# CPSW_CPSW_52800000h register map
Vendor: Texas Instruments
Registers are 32-bit, read-write, reset 0x0 unless marked. A register's access mark holds for its fields unless they carry their own. Offsets are as the file gives them; [hi:lo] are bit positions; {n}, {i} and the like mark numbered series; 'fields as' and 'values as' point back to an identical list.

## CPSW (part 2 of 4)
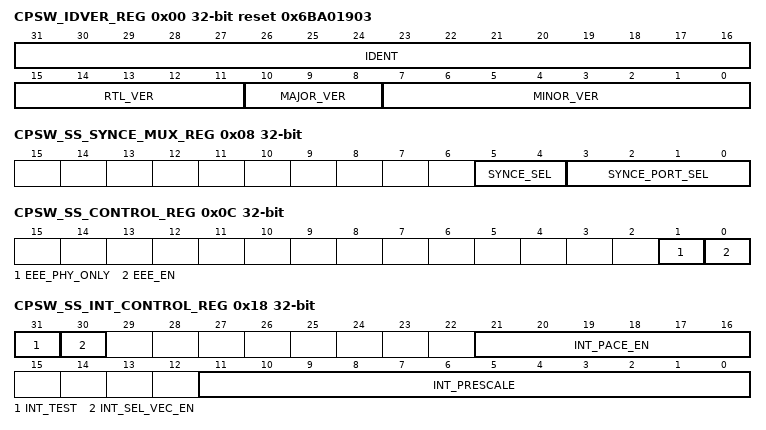
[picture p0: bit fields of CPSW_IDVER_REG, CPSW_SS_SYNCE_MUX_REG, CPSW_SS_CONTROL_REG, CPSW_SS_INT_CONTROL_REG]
0x00 CPSW_IDVER_REG ro reset 0x6BA01903 — ID Version Register.
  [31:16] IDENT — Identification value
  [15:11] RTL_VER — RTL version value
  [10:8] MAJOR_VER — Major version value
  [7:0] MINOR_VER — Minor version value
0x04 CPSW_SS_SYNCE_COUNT_REG — SS SYNCE Count Register.
  [31:0] SYNCE_CNT — SyncE Count Value - This value determines the toggle rate of the TS_SYNCE output. When this value is zero the TS_SYNCE output is disabled (low). When this value is non-zero, the TS_SYNCE output toggles each time the synce count value is reached. If this value is to be changed to another non-zero value then it should be written with a zero value before Writing the new non-zero value.
0x08 CPSW_SS_SYNCE_MUX_REG — SS Synce Mux Register.
  [5:4] SYNCE_SEL — Sync E Interface Select. 00 - GMIIn_MRCLK_I input clock from selected GMII port 01 - RMII_MHZ_50_CLK (same for all ports if RMII included) 10 - RGMIIn_RXC_I input clock from selected port (If RGMII included) 11 - SERDESn_RXCLK from selected port (If SGMII included)
  [3:0] SYNCE_PORT_SEL — Sync E Port Select - This field selects the port that will be used for the synchronous Ethernet receive clock. The port interface is selected with synce_sel. 0 - Port 1 1 - Port 2 ... 7 - Port 8 8-15 - Reserved
0x0C CPSW_SS_CONTROL_REG — SS Control Register.
  [1] EEE_PHY_ONLY — Energy Efficient Enable Phy Only Mode. 0 - The low power indicate state (LPI) includes gating off the CPPI_GCLK to the CPSW. 1 - The low power indicate state (LPI) does not gate the clock to the CPSW
  [0] EEE_EN — Energy Efficient Ethernet Enable. 0 - EEE is disabled 1 - EEE is enabled
0x18 CPSW_SS_INT_CONTROL_REG — SS Interrupt Control Register.
  [31] INT_TEST — Interrupt Test - Test bit to the interrupt pacing blocks
  [30] INT_SEL_VEC_EN — Interrupt Select Vector Enable. 0 - in_vector is an 8-bit mask for tx_pend, rx_pend, and rx_thresh_pend. 1 - in_vector is the 3-bit encoded value of the highest interrupt channel set for tx_pend, rx_pend, and rx_thresh_pend.
  [21:16] INT_PACE_EN — Interrupt Pacing Enable Bus. int_pace_en[0] - Enables C0_Rx_Pulse Pacing (0 is pacing bypass) int_pace_en[1] - Enables C0_Tx_Pulse Pacing (0 is pacing bypass) int_pace_en[2] - Enables C1_Rx_Pulse Pacing (0 is pacing bypass) int_pace_en[3] - Enables C1_Tx_Pulse Pacing (0 is pacing bypass) int_pace_en[4] - Enables C2_Rx_Pulse Pacing (0 is pacing bypass) int_pace_en[5] - Enables C2_Tx_Pulse Pacing (0 is pacing bypass)
  [11:0] INT_PRESCALE — Interrupt Counter Prescaler - The number of VBUSP_CLK periods in 4us.
0x1C CPSW_SS_STATUS_REG ro — SS Status Register.
  [0] EEE_CLKSTOP_ACK — Energy Efficient Ethernet clockstop acknowledge from CPSW
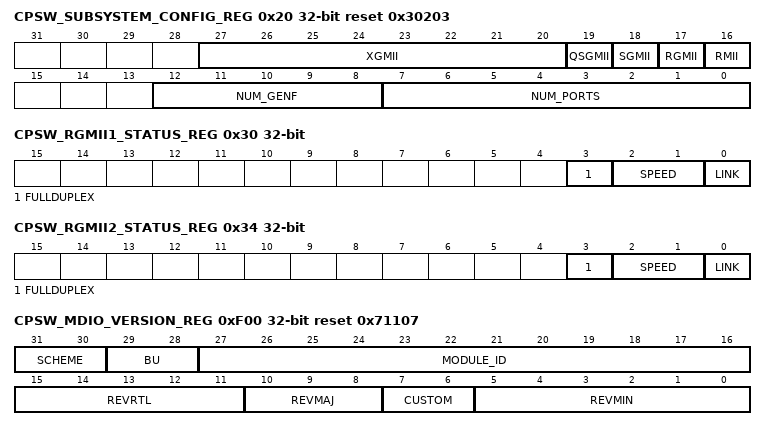
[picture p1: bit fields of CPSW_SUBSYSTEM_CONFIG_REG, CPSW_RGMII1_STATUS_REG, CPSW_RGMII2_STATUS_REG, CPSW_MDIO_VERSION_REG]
0x20 CPSW_SUBSYSTEM_CONFIG_REG ro reset 0x30203 — Subsystem Configuration Register.
  [27:20] XGMII — The Number of XGMII Ports included in the CPSW
  [19] QSGMII — QSGMII is included in the CPSW
  [18] SGMII — SGMII is included in the CPSW
  [17] RGMII — RGMII is included in the CPSW
  [16] RMII — RMII is included in the CPSW
  [12:8] NUM_GENF — The number of CPTS GENF outputs
  [7:0] NUM_PORTS — The total number of ports including the host port 0
0x30 CPSW_RGMII1_STATUS_REG ro — RGMII1 Status Register.
  [3] FULLDUPLEX — Rgmii1 Full-duplex 0 - Half-duplex 1 - Full-duplex
  [2:1] SPEED — Rgmii1 Speed 00 - 10Mbps 01 - 100Mbps 10 - 1000Mbps 11 - reserved
  [0] LINK — Rgmii1 Link Indicator 0 - Link is down 1 - Link is up
0x34 CPSW_RGMII2_STATUS_REG ro — RGMII2 Status Register.
  [3] FULLDUPLEX — Rgmii2 Full-duplex 0 - Half-duplex 1 - Full-duplex
  [2:1] SPEED — Rgmii2 Speed 00 - 10Mbps 01 - 100Mbps 10 - 1000Mbps 11 - reserved
  [0] LINK — Rgmii2 Link Indicator 0 - Link is down 1 - Link is up
0xF00 CPSW_MDIO_VERSION_REG ro reset 0x71107 — MDIO Version Register
  [31:30] SCHEME
  [29:28] BU
  [27:16] MODULE_ID
  [15:11] REVRTL — RTL version
  [10:8] REVMAJ — Major version
  [7:6] CUSTOM — Custom version
  [5:0] REVMIN — Minor version
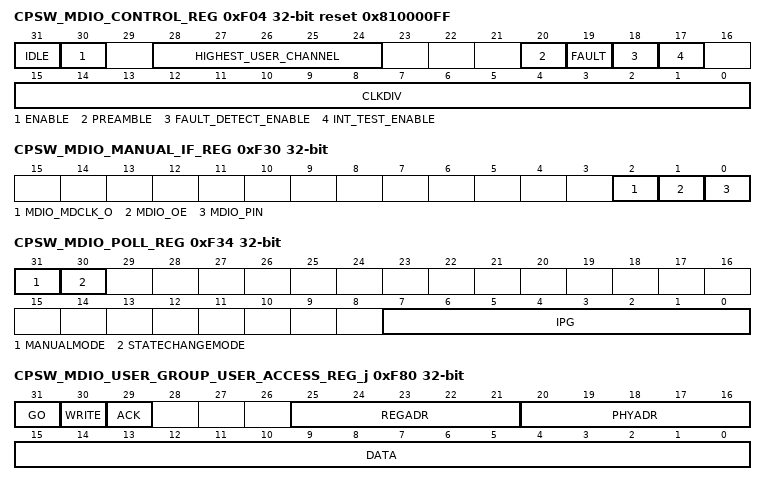
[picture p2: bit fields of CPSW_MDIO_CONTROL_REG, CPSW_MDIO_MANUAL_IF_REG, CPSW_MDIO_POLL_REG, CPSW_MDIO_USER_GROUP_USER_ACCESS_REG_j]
0xF04 CPSW_MDIO_CONTROL_REG access per field reset 0x810000FF — MDIO Control Register
  [31] IDLE ro — MDIO state machine IDLE. Set to 1 by the hardware when the state machine is in the idle state.
  [30] ENABLE rw — Enable control. Writing a 1 to this bit enables the MDIO state machine, writing a 0 disables it. If the MDIO state machine is active at the time it is disabled, it will complete the current operation before halting and setting the idle bit. If using byte access, the enable bit has to be the last bit written in this register.
  [28:24] HIGHEST_USER_CHANNEL ro — Highest user channel. This field specifies the highest useraccess channel that is available in the module and is currently set to 1. This implies that MDIOUserAccess1 is the highest available user access channel.
  [20] PREAMBLE rw — Preamble disable. Writing a 1 to this bit disables this device from sending MDIO frame preambles in clause 22 mode of operation. This bit has no effect in clause 45 mode of operation.
  [19] FAULT rw — Fault indicator. This bit is set to 1 if the MDIO pins fail to read back what the device is driving onto them. This indicates a physical layer fault and the module state machine is reset. Writing a 1 to it clears this bit.
  [18] FAULT_DETECT_ENABLE rw — Fault detect enable. This bit has to be set to 1 to enable the physical layer fault detection.
  [17] INT_TEST_ENABLE rw — Interrupt test enable. This bit can be set to 1 to enable the host to set the userint and linkint bits for test purposes.
  [15:0] CLKDIV rw — Clock Divider. This field specifies the division ratio between CLK and the frequency of MDCLK. MDCLK is disabled when clkdiv is set to 0. MDCLK frequency = clk frequency/(clkdiv+1).
0xF08 CPSW_MDIO_ALIVE_REG — MDIO Alive Register
  [31:0] ALIVE — MDIO Alive. Each of the 32 bits of this register is set if the most recent access to the PHY with address corresponding to the register bit number was acknowledged by the PHY, the bit is reset if the PHY fails to acknowledge the access. Both the user and polling accesses to a PHY will cause the corresponding alive bit to be updated. The alive bits are intended to be used to give an indication of the presence or not of the PHY with the corresponding address. Writing a 1 to any bit will clear it, writing a 0 has no effect.
0xF0C CPSW_MDIO_LINK_REG ro — MDIO Link Register
  [31:0] LINK — MDIO Link state. This register is updated after a read of the Generic Status Register of a PHY. The corresponding bit is set if the PHY with the corresponding address has link and the PHY acknowledges the read transaction. The bit is cleared to zero if the PHY indicates it does not have link or fails to acknowledge the read transaction. Writes to the register have no effect. In addition, in Normal Mode Operation, the status of the two PHYs specified in the MDIOUserPhySel registers can be determined using the MLINK input pins. This is determined by the linksel bit in the MDIOUserPhySel register. In State Change Mode the MLINK input pins are unused.
0xF10 CPSW_MDIO_LINK_INT_RAW_REG — MDIO Link Interrupt Raw Register
  [1:0] LINKINTRAW — MDIO link change event raw value. Normal mode operation: When asserted, a bit indicates that there was an MDIO link change event (i.e. change in the MDIOLink register) corresponding to the PHY address in the MDIOUserPhySel register. linkintraw[0] and linkintraw[1] correspond to MDIOUserPhySel0 and MDIOUserPhysel1, respectively. Writing a 1 will clear the event and writing 0 has no effect. If the int_test bit in the MDIOControl register is set, the host may set linkintraw bits to a 1 which may be used for test purposes. MDIO link change event raw value. State Change Mode operation: The linkintraw[0] bit will be asserted when any bit (for any PHY) in the MDIOAlive or MDIOLink registers changes due to MDIO operations. The linkintraw[1] bit is unused in State Change Mode. State Change Mode allows any state change in any PHY to issue an interrupt. If the int_test bit in the MDIOControl register is set, the host may set the linkintraw[0] bit high which may be used for test purposes.
0xF14 CPSW_MDIO_LINK_INT_MASKED_REG — MDIO Link Interrupt Masked Register
  [1:0] LINKINTMASKED — MDIO link change interrupt masked value. Normal mode operation: When asserted, a bit indicates that there was an MDIO link change event (i.e. change in the MDIOLink register) corresponding to the PHY address in the MDIOUserPhySel register and the corresponding linkint_enable bit was set. linkintmasked[0] and linkintmasked[1] correspond to MDIOUserPhySel0 and MDIOUserPhysel1, respectively. Writing a 1 will clear the interrupt and writing 0 has no effect. These masked interrupt bits are the MDIO_LINKINT[1:0] pin values. MDIO link change interrupt masked value. State Change Mode operation: The linkintmasked[0] bit will be asserted when linkintraw[0] is asserted and when the linkintmaskset bit is set to 1. Writing a 1 will clear linkintmasked[0] (and the MDIO_LINKINT[0] output) and writing 0 has no effect. The linkintmasked[1] bit is not used in State Change Mode (MDIO_LINKINT[1] is therefore also unused in State Change Mode).
0xF18 CPSW_MDIO_LINK_INT_MASK_SET_REG — MDIO Link Interrupt Mask Set Register
  [0] LINKINTMASKSET — MDIO link interrupt mask set. Normal Mode Operation: This register is not used in normal mode. In normal mode the MDIO_LINKINT[1:0] interrupts are enabled with the linkint_enable bit in the associated MDIOUserPhySel0/1 register. MDIO link interrupt mask set. State Change Mode Operation: Writing this bit to 1 will enable the MDIO link status change interrupt (MDIO_LINKINT[0]) to be asserted when linkintraw[0] is asserted.
0xF1C CPSW_MDIO_LINK_INT_MASK_CLEAR_REG — MDIO Link Interrupt Mask Clear Register
  [0] LINKINTMASKCLR — MDIO link interrupt mask clear. Normal Mode Operation: This register is not used in normal mode. In normal mode the MDIO_LINKINT[1:0] interrupts are enabled with the linkint_enable bit in the associated MDIOUserPhySel0/1 register. MDIO link interrupt mask clear. State Change Mode Operation: Writing this bit to 1 will disable the MDIO link status change interrupt (MDIO_LINKINT[0]) regardless of the linkintraw[0] bit value.
0xF20 CPSW_MDIO_USER_INT_RAW_REG — MDIO User Interrupt Raw Register
  [1:0] USERINTRAW — Raw value of MDIO user command complete event for MDIOUserAccess1 through MDIOUserAccess0, respectively. When asserted, a bit indicates that the previously scheduled PHY read or write command using that particular MDIOUserAccess register has completed. Writing a 1 will clear the event and writing 0 has no effect. If the int_test bit in the MDIOControl register is set, the host may set the userintraw bits to a 1. This mode may be used for test purposes.
0xF24 CPSW_MDIO_USER_INT_MASKED_REG — MDIO User Interrupt Masked Register
  [1:0] USERINTMASKED — Masked value of MDIO user command complete interrupt for MDIOUserAccess1 through MDIOUserAccess0, respectively. When asserted, a bit indicates that the previously scheduled PHY read or write command using that particular MDIOUserAccess register has completed and the corresponding userintmaskset bit is set to 1. Writing a 1 will clear the interrupt and writing 0 has no effect. If the int_test bit in the MDIOControl register is set, the host may set the userintmasked bits to a 1. This mode may be used for test purposes.
0xF28 CPSW_MDIO_USER_INT_MASK_SET_REG — MDIO User Interrupt Mask Set Register
  [1:0] USERINTMASKSET — MDIO user interrupt mask set for userintmasked[1:0], respectively. Writing a bit to 1 will enable MDIO user command complete interrupts for that particular MDIOUserAccess register. MDIO user interrupt for a particular MDIOUserAccess register is disabled if the corresponding bit is 0. Writing a 0 to this register has no effect.
0xF2C CPSW_MDIO_USER_INT_MASK_CLEAR_REG — MDIO User Interrupt Mask Clear Register
  [1:0] USERINTMASKCLR — MDIO user command complete interrupt mask clear for userintmasked[1:0], respectively. Writing a bit to 1 will disable further user command complete interrupts for that particular MDIOUserAccess register. Writing a 0 to this register has no effect.
0xF30 CPSW_MDIO_MANUAL_IF_REG — MDIO Manual Interface Register
  [2] MDIO_MDCLK_O — MDIO Clock Output - This value is the MDCLK_O output value when the manualmode bit is set in the MDIO_POLL_IPG register.
  [1] MDIO_OE — MDIO Output Enable - This value is inverted and output on the MDIO_OE_N output when the manualmode bit is set in the MDIO_POLL_IPG register.
  [0] MDIO_PIN — MDIO_Pin Value - This is the external MDIO data pin value when the manualmode bit is set in the MDIO_POLL_IPG register. That is, this value is driven on the MDIO_O (the MDIO serial data output) when MDIO_OE is asserted. The read value for this bit comes from MDIO_I (the MDIO serial data input). If MDIO_OE is asserted and MDIO_PIN is written with a 1 then MDIO_PIN should read a 1 if there are no external devices pulling the MDIO data line low.
0xF34 CPSW_MDIO_POLL_REG — MDIO Poll Register
  [31] MANUALMODE — Polling Inter Packet Gap Value - This value is the number of MDCLK_O clocks between each poll when polling is enabled.
  [30] STATECHANGEMODE — State Change Mode - When set, the MDIO is operating in State Change Mode. When clear, the MDIO is operating in normal mode. State change mode effects interrupt operations.
  [7:0] IPG — Manual Mode - When set, the MDIO pins are directly controlled by software through the bits in the MDIOManual_IF register
0xF38 CPSW_MDIO_POLL_EN_REG reset 0xFFFFFFFF — MDIO Poll Enable Register
  [31:0] POLL_EN — Poll Enable - When set, the bit indicates that the associated PHY will be included in polling operations. When clear, the associated PHY will not be polled. Each bit in this field is associated with a PHY. Bit zero is associated with PHY 0 and so on. Due to a limitation in the hardware, bit 31 must always be set, regardless of the value of the preamble disable bit in the MDIO_CONTROL register. However, there does not have to be a PHY at address 31.
0xF3C CPSW_MDIO_CLAUS45_REG — MDIO Clause45 Register
  [31:0] CLAUSE45 — MDIO clause 45 mode. When a clause45 bit is cleared, the PHY associated with the clause45 bit is operating in the clause 22 mode. When set, the PHY associated with the clause45 bit is operating in the clause 45 mode. Bit 0 is associated with PHY 0 and so on.
0xF40 CPSW_MDIO_USER_ADDR0_REG — MDIO Address 0 Register
  [15:0] USER_ADDR0 — User Address 0 - In clause 45 mode, this field value is the address transferred in the address transfer inititated before each MDIOUserAccess0 access. This is not used for PHYs operating in clause22 mode as there is no address transfer preceeding each MDIOUserAccess0 access.
0xF44 CPSW_MDIO_USER_ADDR1_REG — MDIO Address 1 Register
  [15:0] USER_ADDR1 — User Address 1 - In clause 45 mode, this field value is the address transferred in the address transfer inititated before each MDIOUserAccess1 access. This is not used for PHYs operating in clause22 mode as there is no address transfer preceeding each MDIOUserAccess1 access.
0xF80 CPSW_MDIO_USER_GROUP_USER_ACCESS_REG_j — MDIO User Access Register
  [31] GO — Go. Writing a 1 to this bit causes the MDIO state machine to perform an MDIO access when it is convenient for it to do so, this is not an instantaneous process. Writing a 0 to this bit has no effect. This bit is write able only if the MDIO state machine is enabled. This bit will self clear when the requested access has been completed. Any writes to the MDIOUserAccess0 register are blocked when the go bit is 1. If byte access is being used, the go bit should be written last.
  [30] WRITE — Write enable. Setting this bit to a 1 causes the MDIO transaction to be a register write, otherwise it is a register read.
  [29] ACK — Acknowledge. This bit is set if the PHY acknowledged the read transaction.
  [25:21] REGADR — Register address. This field specifies the PHY register to be accessed for this transaction in clause 22 mode or the MMD value in clause 45 mode.
  [20:16] PHYADR — PHY address. This field specifies the PHY to be accessed for this transaction.
  [15:0] DATA — User data. The data value read from or to be written to the specified PHY register.
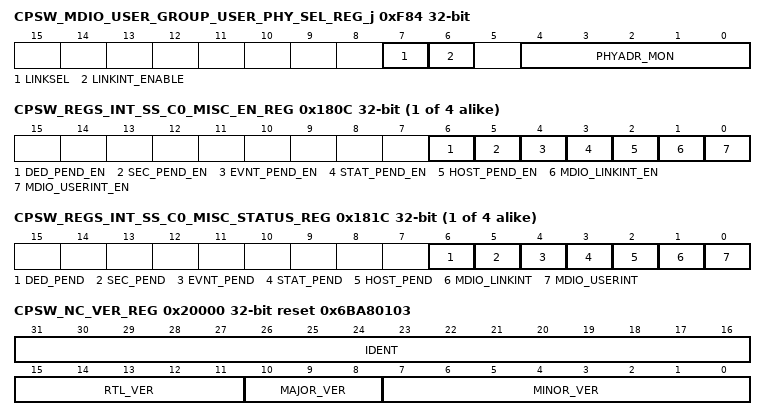
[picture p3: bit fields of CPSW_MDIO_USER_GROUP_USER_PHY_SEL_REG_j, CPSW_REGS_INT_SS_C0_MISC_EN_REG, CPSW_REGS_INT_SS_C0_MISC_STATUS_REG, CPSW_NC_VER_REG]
0xF84 CPSW_MDIO_USER_GROUP_USER_PHY_SEL_REG_j — MDIO User PHY Select Register
  [7] LINKSEL — Link status determination select. Set to 1 to determine link status using the MLINK pin. Default value is 0 which implies that the link status is determined by the MDIO state machine.
  [6] LINKINT_ENABLE — Link change interrupt enable. Set to 1 to enable link change status interrupts for PHY address specified in phyadr_mon. Link change interrupts are disabled if this bit is set to 0.
  [4:0] PHYADR_MON — PHY address whose link status is to be monitored.
{0x1800+0x40*i} CPSW_REGS_INT_SS_C{i}_TH_THRESH_PULSE_EN_REG (i=0..3) — Core {i} THost Threshold Pulse Interrupt Enable Register
  [7:0] TH_THRESH_PULSE_EN — Core {i} THost Threshold Enable - Each bit in this register corresponds to the bit in the THost threshold interrupt that is enabled to generate an interrupt on C{i}_TH_THRESH_PULSE.
{0x1804+0x40*i} CPSW_REGS_INT_SS_C{i}_TH_PULSE_EN_REG (i=0..3) — Core {i} THost Pulse Interrupt Enable Register
  [7:0] TH_PULSE_EN — Core {i} THost Enable - Each bit in this register corresponds to the bit in the THost interrupt that is enabled to generate an interrupt on C{i}_TH_PULSE.
{0x1808+0x40*i} CPSW_REGS_INT_SS_C{i}_FH_PULSE_EN_REG (i=0..3) — Core {i} FHost Pulse Interrupt Enable Register
  [7:0] FH_PULSE_EN — Core {i} FHost Interrupt Enable - Each bit in this register corresponds to the bit in the FHost interrupt that is enabled to generate an interrupt on C{i}_FH_PULSE.
{0x180C+0x40*i} CPSW_REGS_INT_SS_C{i}_MISC_EN_REG (i=0..3) — Core {i} Misc Interrupt Enable Register
  [6] DED_PEND_EN — Core {i} MISC DED Memory Protect Error Interrupt Enable - enabled to generate an interrupt on C{i}_Misc_PULSE
  [5] SEC_PEND_EN — Core {i} MISC SEC Memory Protect Error Interrupt Enable - enabled to generate an interrupt on C{i}_Misc_PULSE
  [4] EVNT_PEND_EN — Core {i} MISC CPTS Event Interrupt Enable - enabled to generate an interrupt on C{i}_Misc_PULSE
  [3] STAT_PEND_EN — Core {i} MISC Statistics Interrupt Enable - Logical OR of all port statistics bits (bits n downto 0) - enabled to generate an interrupt on C{i}_Misc_PULSE
  [2] HOST_PEND_EN — Core {i} MISC Host Interrupt Enable - enabled to generate an interrupt on C{i}_Misc_PULSE
  [1] MDIO_LINKINT_EN — Core {i} MISC MDIO linkint - Logical OR of bits 1 and 0 - enabled to generate an interrupt on C{i}_Misc_PULSE
  [0] MDIO_USERINT_EN — Core {i} MISC_MDIO userint interrupt enable - Logical OR of bits 1 and 0 - enabled to generate an interrupt on C{i}_Misc_PULSE
{0x1810+0x40*i} CPSW_REGS_INT_SS_C{i}_TH_THRESH_PULSE_STATUS_REG ro (i=0..3) — THost Threshold Pulse Interrupt Status Register
  [7:0] TH_THRESH_PULSE_STATUS — Core {i} THost Threshold Masked Interrupt Status - Each bit in this read only register corresponds to the bit in the THost threshold interrupt that is enabled and generating an interrupt on C{i}_TH_THRESH_PULSE.
{0x1814+0x40*i} CPSW_REGS_INT_SS_C{i}_TH_PULSE_STATUS_REG ro (i=0..3) — THost Pulse Interrupt Status Register
  [7:0] TH_PULSE_STATUS — Core {i} THost Pulse Interrupt Status Register - Each bit in this read only register corresponds to the bit in the Rx interrupt that is enabled and generating an interrupt on C{i}_TH_PULSE.
{0x1818+0x40*i} CPSW_REGS_INT_SS_C{i}_FH_PULSE_STATUS_REG ro (i=0..3) — FHost Pulse Interrupt Status Register
  [7:0] FH_PULSE_STATUS — Core {i} FHost Pulse Interrupt Status Register - Each bit in this read only register corresponds to the bit in the Tx interrupt that is enabled and generating an interrupt on C{i}_FH_PULSE .
{0x181C+0x40*i} CPSW_REGS_INT_SS_C{i}_MISC_STATUS_REG (i=0..3) — Misc Interrupt Status Register - Set bits in this register indicate that an enabled interrupt is asserted
  [6] DED_PEND — Core {i} MISC DED Memory Protect Error Interrupt
  [5] SEC_PEND — Core {i} MISC SEC Memory Protect Error Interrupt
  [4] EVNT_PEND — Core {i} MISC CPTS Event Interrupt
  [3] STAT_PEND — Core {i} MISC Statistics Interrupt - Logical OR of bits n downto 0
  [2] HOST_PEND — Core {i} MISC Host Interrupt Enable
  [1] MDIO_LINKINT — Core {i} MISC MDIO linkint - Logical OR of bits 1 and 0
  [0] MDIO_USERINT — Core {i} MISC_MDIO userint interrupt - Logical OR of bits 1 and 0
{0x1820+0x40*i} CPSW_REGS_INT_SS_C{i}_TH_IMAX_REG (i=0..3) — Core {i} THost Interrupt Max Register Register
  [5:0] TH_IMAX — Core {i} THost Interrupts per millisecond - The maximum number of interrupts per millisecond generated on C{i}_TH_PULSE if pacing is enabled for this interrupt.
{0x1824+0x40*i} CPSW_REGS_INT_SS_C{i}_FH_IMAX_REG (i=0..3) — Core {i} FHost Interrupt Max Register Register
  [5:0] FH_IMAX — Core {i} FHost Interrupts per millisecond - The maximum number of interrupts per millisecond generated on C{i}_FH_PULSE if pacing is enabled for this interrupt.
0x20000 CPSW_NC_VER_REG ro reset 0x6BA80103 — CPSW ID Version
  [31:16] IDENT — Identification Value
  [15:11] RTL_VER — RTL Version Value
  [10:8] MAJOR_VER — Major Version Value
  [7:0] MINOR_VER — Minor Version Value
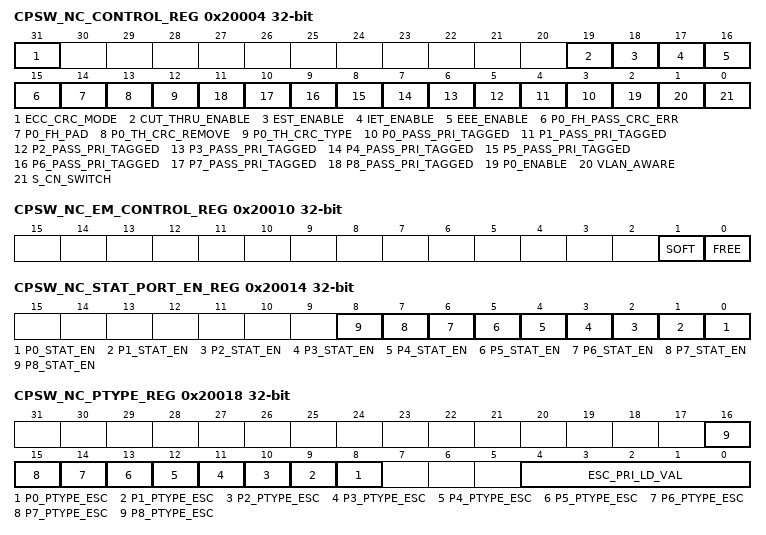
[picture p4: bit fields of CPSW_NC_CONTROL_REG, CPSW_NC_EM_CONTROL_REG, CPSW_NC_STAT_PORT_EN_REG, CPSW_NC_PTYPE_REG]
0x20004 CPSW_NC_CONTROL_REG — CPSW Switch Control
  [31] ECC_CRC_MODE — ECC CRC Mode - 0 - ECC errors induced through the ECC aggregator flip bits in the packet headers (not in packet data). 1 - ECC errors induced through the ECC aggregator flip bits in the packet data (not in the packet headers).
  [19] CUT_THRU_ENABLE — Cut Thru Enable - 0 - Cut Thru disabled. 1 - Cut Thru enabled .
  [18] EST_ENABLE — Enhanced Scheduled Traffic enable (EST) - 0 - EST is disabled. 1 - EST is enabled
  [17] IET_ENABLE — Intersperced Express Traffic enable (IET) - 0 - IET is disabled. 1 - IET is enabled.
  [16] EEE_ENABLE — Energy Efficient Ethernet enable - 0 - Energy Efficient Ethernet is disabled. 1 - Energy Efficient Ethernet is enabled.
  [15] P0_FH_PASS_CRC_ERR — Port 0 Pass Received CRC errors - 0 - Packets received with CRC errors on port 0 are dropped. 1 - Packets received with CRC errors on port 0 are transferred to the destination ports.
  [14] P0_FH_PAD — Port 0 Receive Short Packet Pad - 0 - short packets are dropped. 1 - short packets are padded to 64-bytes (with pad and added CRC) if the CRC is not passed in. Short packets are dropped if the CRC is passed (in the Info0 word).
  [13] P0_TH_CRC_REMOVE — Port 0 Transmit CRC remove - 0 - Do not remove the CRC on Port 0 THost (egress) packets. 1 - Remove the CRC on all Port 0 THost (egress) packets.
  [12] P0_TH_CRC_TYPE — Port 0 Transmit CRC type - The type of CRC on all Port 0 transmit packets (egress), regardless of the CRC type of in ingress Ethernet port. This bit is present only if psi_cast = 1. 0 - Ethernet CRC on Port 0 Egress. 1 - Castagnoli CRC on Port 0 Egress (if psi_cast = 1).
  [n+3] P{n}_PASS_PRI_TAGGED (n=0..8) — Port {n} Pass Priority Tagged - 0 - Priority tagged packets have the zero VID replaced with the input port Enet_P{n}_PORT_VLAN[11:0] on ingress. 1 - Priority tagged packets are processed unchanged.
  [2] P0_ENABLE — Port 0 Enable - 0 - Port 0 is disabled 1 - Port 0 is enabled
  [1] VLAN_AWARE — VLAN Aware Mode - 0 - CPSW_NU is in the VLAN unaware mode. 1 - CPSW_NU is in the VLAN aware mode.
  [0] S_CN_SWITCH — Service or Customer VLAN switch. 0 - Customer switch. VLAN processing uses the inner_vlan_ltype. 1 - Service switch. VLAN processing uses the outer_vlan_ltype.
0x2000C CPSW_NC_STATUS_REG ro reset 0x1 — CPSW Status
  [0] CPPI_IDLE — CPPI Idle - Indicates when set that the CPPI port transmit and receive are idle.
0x20010 CPSW_NC_EM_CONTROL_REG — CPSW Emulation Control
  [1] SOFT — Emulation Soft Bit
  [0] FREE — Emulation Free Bit
0x20014 CPSW_NC_STAT_PORT_EN_REG — CPSW Statistics Port Enable
  [n] P{n}_STAT_EN (n=0..8) — Port {n} Statistics Enable 0 - Statistics are disabled for the port. 1 - Statistics are enabled for the port.
0x20018 CPSW_NC_PTYPE_REG — CPSW Transmit Priority Type
  [n+8] P{n}_PTYPE_ESC (n=0..8) — Port {n} Priority Type Escalate - 0 - Priority Type Fixed. 1 - Priority Type Escalate
  [4:0] ESC_PRI_LD_VAL — Escalate Priority Load Value - When a port is in escalate priority, this is the number of higher priority packets sent before the next lower priority is allowed to send a packet. Escalate priority allows lower priority packets to be sent at a fixed rate relative to the next higher priority. The min value of esc_pri_ld_val = 2.
0x2001C CPSW_NC_SOFT_IDLE_REG — CPSW Software Idle
  [0] SOFT_IDLE — Software Idle - 0 - Software idle not commanded. 1 - Command CPSW software idle. When set, port 0 packet DMA operations stop at the next packet boundary.
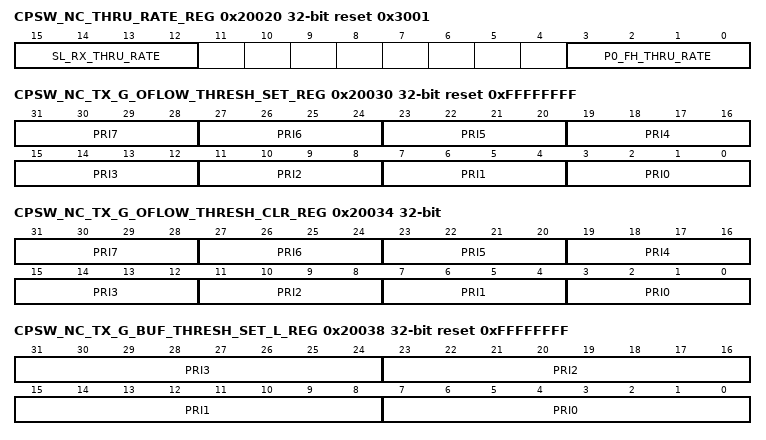
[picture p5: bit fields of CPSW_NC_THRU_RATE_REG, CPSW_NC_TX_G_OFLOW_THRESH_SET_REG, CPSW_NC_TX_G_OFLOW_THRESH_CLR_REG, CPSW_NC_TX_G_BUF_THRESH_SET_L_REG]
0x20020 CPSW_NC_THRU_RATE_REG reset 0x3001 — CPSW Thru Rate
  [15:12] SL_RX_THRU_RATE — This is not a field intended to be changed by software
  [3:0] P0_FH_THRU_RATE — This is not a field intended to be changed by software
0x20024 CPSW_NC_GAP_THRESH_REG reset 0xB — CPSW Transmit FIFO Short Gap Threshold
  [4:0] GAP_THRESH — Ethernet Port Short Gap Threshold - This is the Ethernet port associated FIFO transmit block usage value for triggering transmit short gap (when short gap is enabled).
0x2002C CPSW_NC_EEE_PRESCALE_REG — CPSW Energy Efficient Ethernet Prescale Value
  [11:0] EEE_PRESCALE — Energy Efficient Ethernet Prescale count load value - This value is loaded into the EEE pre-scale counter each time the pre-scale count decrements to zero. The EEE counters are enabled to decrement each time the pre-scale counter reaches zero (and the EEE counters are enabled to count time). If this value is zero then the EEE counters decrement on every clock. If this value is 0x001 then the counters decrement on every other clock (and so on).
0x20030 CPSW_NC_TX_G_OFLOW_THRESH_SET_REG reset 0xFFFFFFFF — CPSW PFC Tx Global Out Flow Threshold Set
  [4n+3:4n] PRI{n} (n=0..7) — Priority Based Flow Control Global Outflow Usage Threshold for Pri {n}
0x20034 CPSW_NC_TX_G_OFLOW_THRESH_CLR_REG — CPSW PFC Tx Global Out Flow Threshold Clear
  fields as CPSW_NC_TX_G_OFLOW_THRESH_SET_REG
0x20038 CPSW_NC_TX_G_BUF_THRESH_SET_L_REG reset 0xFFFFFFFF — CPSW PFC Global Tx Buffer Threshold Set Low
  [8n+7:8n] PRI{n} (n=0..3) — Priority Based Flow Control Global Buffer Usage Threshold for Priority {n}
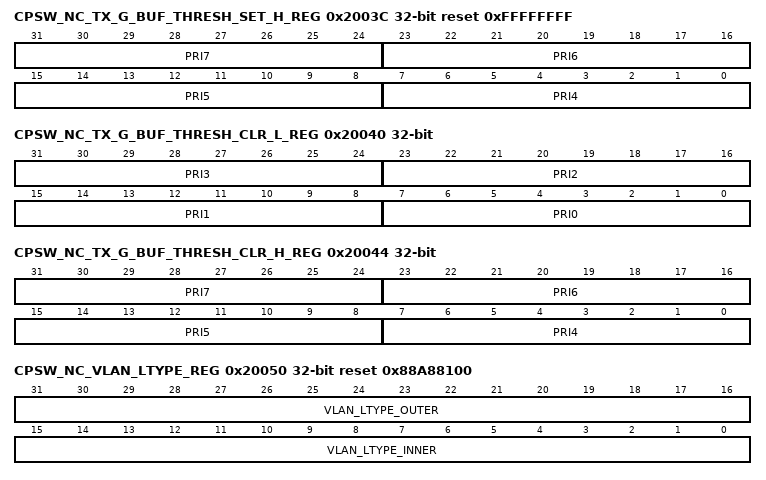
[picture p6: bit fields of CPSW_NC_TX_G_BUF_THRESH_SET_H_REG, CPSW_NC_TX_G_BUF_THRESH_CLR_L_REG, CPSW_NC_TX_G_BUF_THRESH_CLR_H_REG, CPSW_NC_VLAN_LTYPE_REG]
0x2003C CPSW_NC_TX_G_BUF_THRESH_SET_H_REG reset 0xFFFFFFFF — CPSW PFC Global Tx Buffer Threshold Set High
  [8n-25:8n-32] PRI{n} (n=4..7) — Priority Based Flow Control Global Buffer Usage Threshold for Priority {n}
0x20040 CPSW_NC_TX_G_BUF_THRESH_CLR_L_REG — CPSW PFC Global Tx Buffer Threshold Clear Low
  fields as CPSW_NC_TX_G_BUF_THRESH_SET_L_REG
0x20044 CPSW_NC_TX_G_BUF_THRESH_CLR_H_REG — CPSW PFC Global Tx Buffer Threshold Clear High
  fields as CPSW_NC_TX_G_BUF_THRESH_SET_H_REG
0x20050 CPSW_NC_VLAN_LTYPE_REG reset 0x88A88100 — VLAN Length/type
  [31:16] VLAN_LTYPE_OUTER — Outer VLAN LType
  [15:0] VLAN_LTYPE_INNER — Inner VLAN LType
0x20054 CPSW_NC_EST_TS_DOMAIN_REG — Enhanced Scheduled Traffic Host Event Domain
  [7:0] EST_TS_DOMAIN — Enhanced Scheduled Traffic domain. This value is used as the domain in the CPTS event to indicate that the event came from EST.
0x20058 CPSW_NC_CUT_THRESHOLD_REG — Cut-thru Threshold
  [3:0] CUT_THRESH — Cut-thru Threshold - This is not intended to be changed by software
0x2005C CPSW_NC_FREQUENCY_REG — CPSW CPPI_CLK Frequency in Mhz
  [9:0] CPSW_FREQ — CPSW Frequency - This is the frequency in Mhz of the VBUSP_GCLK. The frequency is rounded to the nearest Mhz. This value is used in auto speed detection for cut-thru operations.
0x20060 CPSW_NC_CUT_IET_HOLD_CNT_LD_VAL_REG reset 0x64 — IET Hold Count Load Value
  [7:0] CUT_IET_HOLD_CNT_LD_VAL — Cut-thru IET Hold Count Load Value - This value is loaded into counters to count the time that cut-thru packets are allowed to prempt traffic in advance in order to reduce cut-thru latency with IET operations. This is not intended to be changed by software.
{0x20100+4i} CPSW_NC_TX_PRI{i}_MAXLEN_REG reset 0x7E8 (i=0..7) — Transmit Priority {i} Maximum Length
  [13:0] TX_PRI{i}_MAXLEN — This value determines the maximum packet length that will be transmitted on priority {i} Ethernet egress for all Ethernet ports. The packet length compared to the maximum length value is the ingress packet length (not the actual egress packet length which is the length before VLAN addition or removal or any other egress processing). Packets on a priority that are larger than this value are dropped.
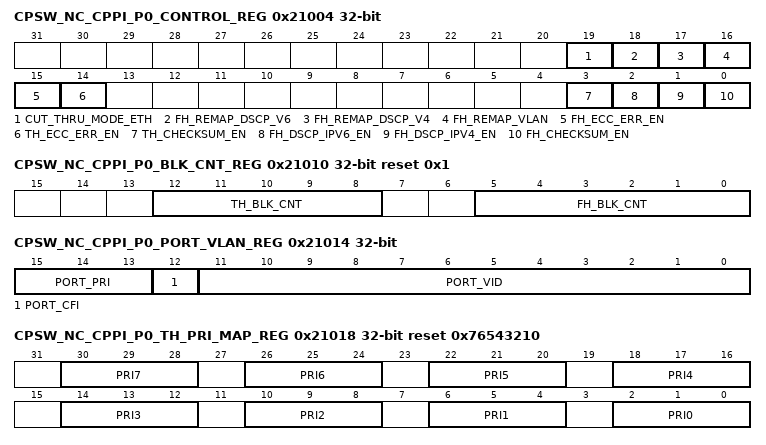
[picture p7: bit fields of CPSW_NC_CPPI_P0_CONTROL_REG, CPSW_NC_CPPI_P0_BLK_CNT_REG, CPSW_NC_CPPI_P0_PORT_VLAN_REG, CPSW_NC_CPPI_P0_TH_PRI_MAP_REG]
0x21004 CPSW_NC_CPPI_P0_CONTROL_REG — CPPI Port 0 Control
  [19] CUT_THRU_MODE_ETH — Port 0 Cut-Thru Mode - Packets always egress from the host port (CPPI egress) store-and-forward regardless of this bit setting. This bit determines how a receive port operates when the host port is in a cut-thru packet destination mask. (present when = 1) 0 - Force packets with the host port in the destination mask to be store-and-forward to all destination ports. 1 - The host port operates similar to Ethernet ports. A cut-thru packet with the host in the destination mask will not force the packet to be store-and-forward unless the cut-thru packet is held off due to word counts or because another cut-thru packet is on the host port priority.
  [18] FH_REMAP_DSCP_V6 — Port 0 FHost (ingress) remap priority to DSCP IPV6 priority (see packet priority handling section for details). 0 - Hardware switch priority IPV6 DSCP priority remapping is disabled. 1 - Hardware switch priority IPV6 DSCP priority remapping is enabled.
  [17] FH_REMAP_DSCP_V4 — Port 0 FHost (ingress) remap priority to DSCP IPV4 priority (see packet priority handling section for details). 0 - Hardware switch priority IPV4 DSCP priority remapping is disabled. 1 - Hardware switch priority IPV4 DSCP priority remapping is enabled.
  [16] FH_REMAP_VLAN — Port 0 receive (ingress) remap priority to VLAN. See priority remapping section for details.
  [15] FH_ECC_ERR_EN — Port 0 FHost ECC Error Enable. This bit must be set to enable FHost ECC error operations
  [14] TH_ECC_ERR_EN — Port 0 THost ECC Error Enable. This bit must be set to enable THost ECC error operations.
  [3] TH_CHECKSUM_EN — Port 0 THost (egress) Checksum Enable 0 - THost checksum is disabled. 1 - THost checksum is enabled. IPV4/V6 Packets have checksum information (4-bytes) included at the end of the packet data when the chksum_encap descriptor bit is set in the EOP THost buffer descriptor.
  [2] FH_DSCP_IPV6_EN — Port 0 FHost IPv6 DSCP enable 0 - Ipv6 DSCP priority mapping is disabled. 1 - Ipv6 DSCP priority mapping is enabled.
  [1] FH_DSCP_IPV4_EN — Port 0 FHost IPv4 DSCP enable 0 - Ipv4 DSCP priority mapping is disabled. 1 - Ipv4 DSCP priority mapping is enabled.
  [0] FH_CHECKSUM_EN — Port 0 FHost (port 0 ingress) Checksum Enable 0 - FHost checksum is disabled. 1 - FHost checksum is enabled. Four bytes of checksum information can be included at the start of the packet data to be used for checksum packet processing when chksum_encap is set in the SOP FHost buffer descriptor.
0x21010 CPSW_NC_CPPI_P0_BLK_CNT_REG ro reset 0x1 — CPPI Port 0 FIFO Block Usage Count
  [12:8] TH_BLK_CNT — Port 0 Transmit Block Count Usage - This value is the number of blocks allocated to the FIFO logical transmit queues. note: for N=2 this field is always zero (no transmit FIFO).
  [5:0] FH_BLK_CNT — Port 0 Receive Block Count Usage - This value is the number of blocks allocated in the receive FIFO.
0x21014 CPSW_NC_CPPI_P0_PORT_VLAN_REG — CPPI Port 0 VLAN
  [15:13] PORT_PRI — Port VLAN Priority
  [12] PORT_CFI — Port CFI bit
  [11:0] PORT_VID — Port VLAN ID
0x21018 CPSW_NC_CPPI_P0_TH_PRI_MAP_REG reset 0x76543210 — CPPI Port 0 Tx Header Pri to Switch Pri Mapping
  [4n+2:4n] PRI{n} (n=0..7) — Priority {n} - A packet header priority of 0x7 is given this switch queue priority.
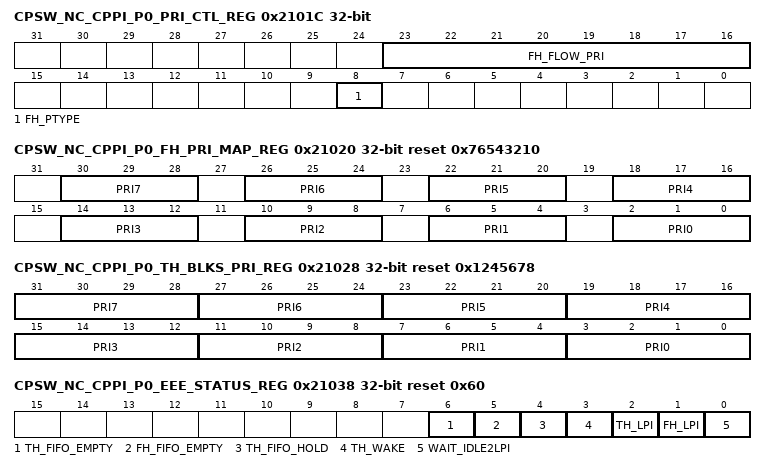
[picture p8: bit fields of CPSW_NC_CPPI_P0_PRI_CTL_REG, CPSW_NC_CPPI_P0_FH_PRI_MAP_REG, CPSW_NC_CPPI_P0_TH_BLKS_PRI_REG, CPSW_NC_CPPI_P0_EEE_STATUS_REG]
0x2101C CPSW_NC_CPPI_P0_PRI_CTL_REG — CPPI Port 0 Priority Control
  [23:16] FH_FLOW_PRI — Receive Priority Based Flow Control Enable (per priority). Note: for N=2 this field should remain zero.
  [8] FH_PTYPE — Receive Priority Type
0x21020 CPSW_NC_CPPI_P0_FH_PRI_MAP_REG reset 0x76543210 — CPPI Port 0 RX Pkt Pri to Header Pri Map
  [4n+2:4n] PRI{n} (n=0..7) — Priority {n} - A packet priority of {0x0+n} is mapped (changed) to this header packet priority.
0x21024 CPSW_NC_CPPI_P0_FH_MAXLEN_REG reset 0x5EE — CPPI Port 0 Receive Frame Max Length
  [13:0] FH_MAXLEN — Port 0 Ingress Maximum Frame Length - This field determines the maximum length of a received frame. The reset value is 1518 (dec). Frames with byte counts greater than p0_fh_maxlen are long frames. Long frames with no errors are oversized frames. Long frames with CRC, code, or alignment error are jabber frames. The maximum value is 9604 (including VLAN) when the CPSW is configured with 1 = 4. When 1 = 1 the maximum value is 2024 (including VLAN).
0x21028 CPSW_NC_CPPI_P0_TH_BLKS_PRI_REG reset 0x1245678 — CPPI Port 0 Transmit Block Sub Per Priority
  [4n+3:4n] PRI{n} (n=0..7) — Priority {n} Port Transmit Blocks
0x21030 CPSW_NC_CPPI_P0_IDLE2LPI_REG — Port 0 EEE Idle to LPI counter
  [23:0] COUNT — Port 0 EEE Idle to LPI counter load value - After CLKSTOP_REQ is asserted, this value is loaded into the port 0 idle to LPI counter on each clock that the port 0 transmit is not idle. Port 0 enters the transmit LPI state when this counter decrements to zero. This counter decrements each time the EEE prescale counter decrements to zero.
0x21034 CPSW_NC_CPPI_P0_LPI2WAKE_REG — Port 0 EEE LPI to wake counter
  [23:0] COUNT — Port 0 EEE LPI to wake counter load value - When the port is in the transmit LPI state and the CLKSTOP_REQ signal is deasserted, this value is loaded into the port 0 LPI to wake counter. Transmit packet operations may begin (resume) when the LPI to wake count decrements to zero (on the pre-scale count). This is the time that the CPDMA transmit must wait before transmit (switch ingress) packet operations begin (resume after wakeup).
0x21038 CPSW_NC_CPPI_P0_EEE_STATUS_REG ro reset 0x60 — Port 0 EEE status
  [6] TH_FIFO_EMPTY — CPPI port 0 transmit FIFO (switch egress) is empty - contains no packets
  [5] FH_FIFO_EMPTY — CPPI port 0 receive FIFO (switch ingress) is empty - contains no packets
  [4] TH_FIFO_HOLD — CPPI port 0 transmit FIFO hold - asserted in the LPI state and during the LPI2WAKE count time
  [3] TH_WAKE — CPPI port 0 transmit wakeup - asserted in the transmit LPI2WAKE count time
  [2] TH_LPI — CPPI port 0 transmit LPI state - asserted when the port 0 transmit is in the LPI state
  [1] FH_LPI — CPPI port 0 receive LPI state - asserted when the port 0 receive is in the LPI state
  [0] WAIT_IDLE2LPI — CPPI port 0 wait idle to LPI - asserted when port 0 is counting the IDLE2LPI time
0x21050 CPSW_NC_CPPI_P0_FIFO_STATUS_REG ro — Port 0 FIFO Status
  [7:0] TH_PRI_ACTIVE — Port 0 Transmit FIFO Priority Active. Each bit indicates whether the corresponding FIFO priority has one or more queued packets on it or not. note: for N=2 this field is always zero (there is no transmit FIFO).
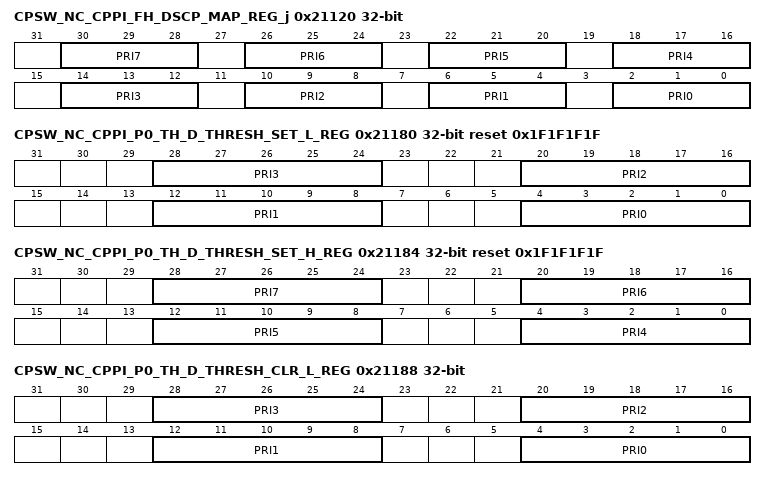
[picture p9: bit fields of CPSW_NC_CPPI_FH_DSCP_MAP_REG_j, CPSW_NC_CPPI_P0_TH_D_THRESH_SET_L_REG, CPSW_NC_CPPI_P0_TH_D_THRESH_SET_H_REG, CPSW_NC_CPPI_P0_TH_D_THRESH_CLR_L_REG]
0x21120 CPSW_NC_CPPI_FH_DSCP_MAP_REG_j — CPPI Receive IPV4/IPV6 DSCP Map N
  [4n+2:4n] PRI{n} (n=0..7) — A DSCP IPV4/V6 packet TOS {n} is mapped to this received priority
0x21140 CPSW_NC_CPPI_P0_PRI_CIR_REG_j — CPPI Port 0 Rx Priority P Committed Information Rate
  [27:0] PRI_CIR — Priority N Committed Information Rate
0x21160 CPSW_NC_CPPI_P0_PRI_EIR_REG_j — CPPI Port 0 Rx Priority P Excess Information Rate
  [27:0] PRI_EIR — Priority N Excess Information Rate
0x21180 CPSW_NC_CPPI_P0_TH_D_THRESH_SET_L_REG reset 0x1F1F1F1F — CPPI Port 0 Tx PFC Destination Threshold Set Low
  [8n+4:8n] PRI{n} (n=0..3) — Port Priority Based Flow Control Threshold Set Value for Priority {n}
0x21184 CPSW_NC_CPPI_P0_TH_D_THRESH_SET_H_REG reset 0x1F1F1F1F — CPPI Port 0 Tx PFC Destination Threshold Set High
  [8n-28:8n-32] PRI{n} (n=4..7) — Port Priority Based Flow Control Threshold Set Value for Priority {n}
0x21188 CPSW_NC_CPPI_P0_TH_D_THRESH_CLR_L_REG — CPPI Port 0 Tx PFC Destination Threshold Clr Low
  [8n+4:8n] PRI{n} (n=0..3) — Port Priority Based Flow Control Threshold Clear Value for Priority {n}
